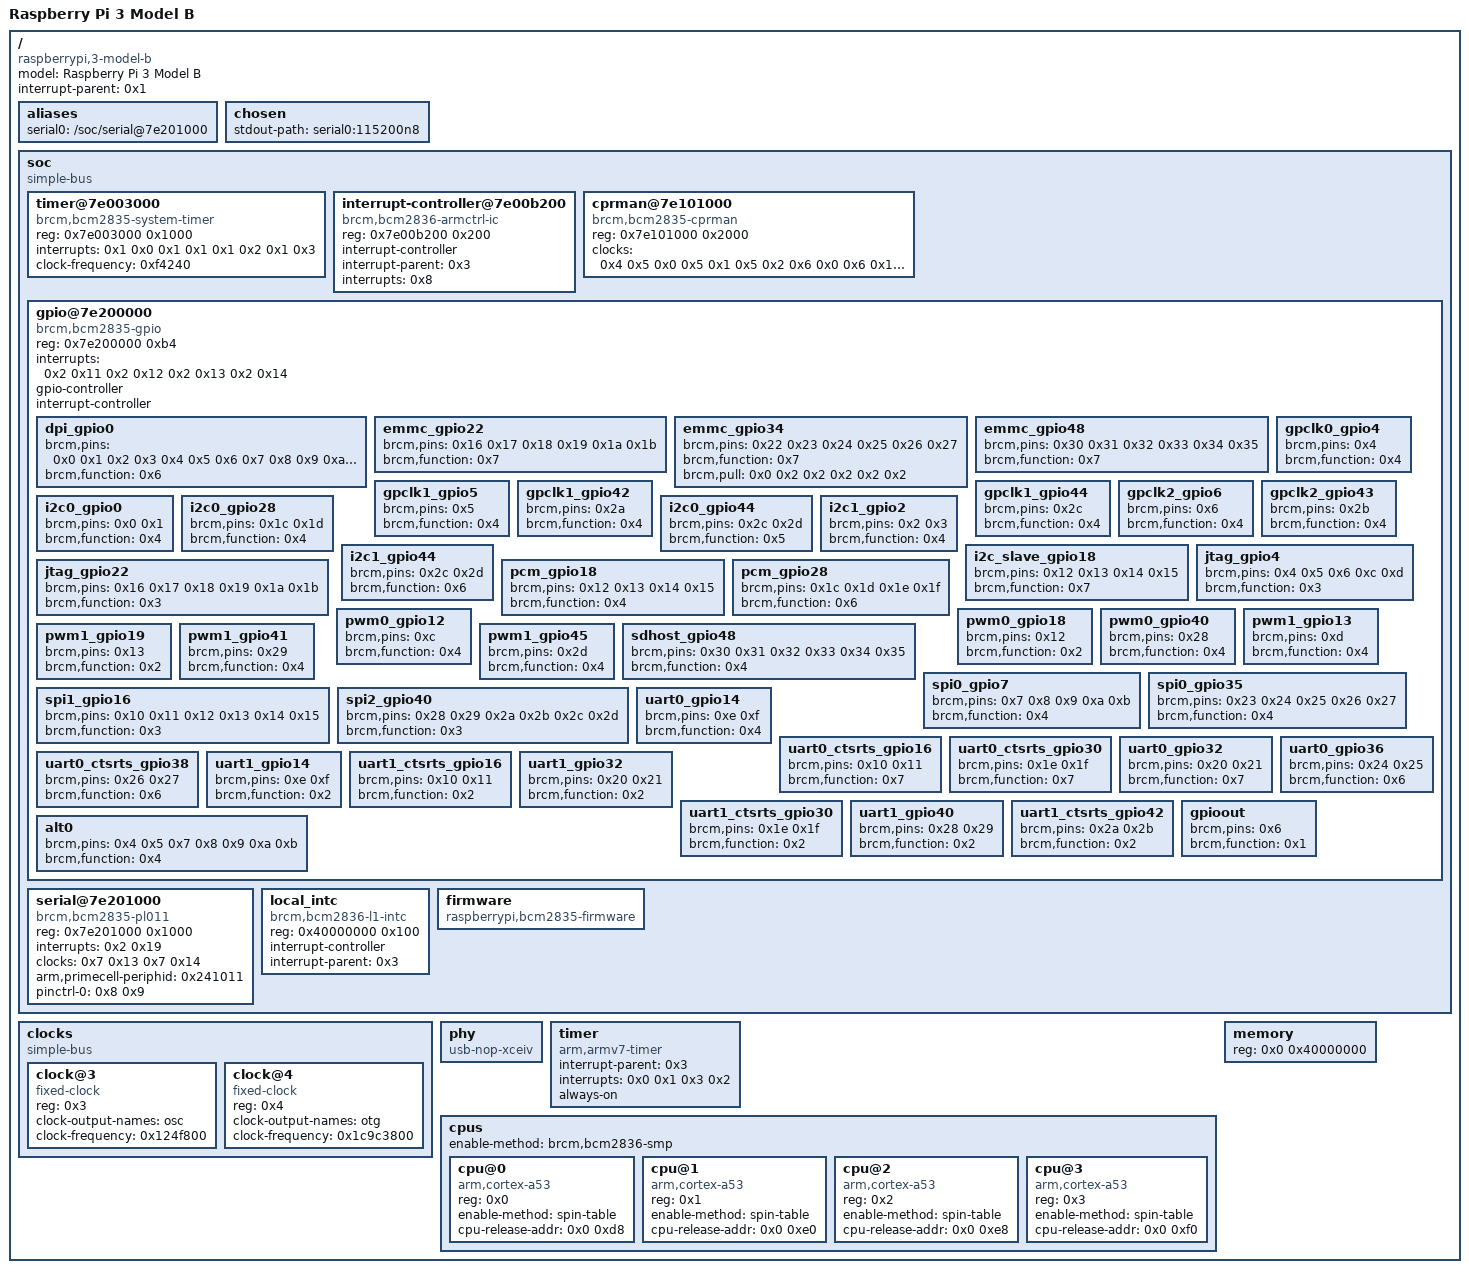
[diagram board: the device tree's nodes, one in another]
/dts-v1/;

/memreserve/	0x0000000000000000 0x0000000000001000;
/ {
	compatible = "raspberrypi,3-model-b", "brcm,bcm2837";
	model = "Raspberry Pi 3 Model B";
	interrupt-parent = <0x1>;
	#address-cells = <0x1>;
	#size-cells = <0x1>;

	aliases {
		serial0 = "/soc/serial@7e201000";
	};

	chosen {
		stdout-path = "serial0:115200n8";
	};

	soc {
		compatible = "simple-bus";
		#address-cells = <0x1>;
		#size-cells = <0x1>;
		ranges = <0x7e000000 0x3f000000 0x1000000 0x40000000 0x40000000 0x1000>;

		timer@7e003000 {
			compatible = "brcm,bcm2835-system-timer";
			reg = <0x7e003000 0x1000>;
			interrupts = <0x1 0x0 0x1 0x1 0x1 0x2 0x1 0x3>;
			clock-frequency = <0xf4240>;
		};

		interrupt-controller@7e00b200 {
			compatible = "brcm,bcm2836-armctrl-ic";
			reg = <0x7e00b200 0x200>;
			interrupt-controller;
			#interrupt-cells = <0x2>;
			interrupt-parent = <0x3>;
			interrupts = <0x8>;
			linux,phandle = <0x1>;
			phandle = <0x1>;
		};

		cprman@7e101000 {
			compatible = "brcm,bcm2835-cprman";
			#clock-cells = <0x1>;
			reg = <0x7e101000 0x2000>;
			clocks = <0x4 0x5 0x0 0x5 0x1 0x5 0x2 0x6 0x0 0x6 0x1 0x6 0x2>;
			linux,phandle = <0x7>;
			phandle = <0x7>;
		};

		gpio@7e200000 {
			compatible = "brcm,bcm2835-gpio";
			reg = <0x7e200000 0xb4>;
			interrupts = <0x2 0x11 0x2 0x12 0x2 0x13 0x2 0x14>;
			gpio-controller;
			#gpio-cells = <0x2>;
			interrupt-controller;
			#interrupt-cells = <0x2>;
			pinctrl-names = "default";
			linux,phandle = <0x19>;
			phandle = <0x19>;

			dpi_gpio0 {
				brcm,pins = <0x0 0x1 0x2 0x3 0x4 0x5 0x6 0x7 0x8 0x9 0xa 0xb 0xc 0xd 0xe 0xf 0x10 0x11 0x12 0x13 0x14 0x15 0x16 0x17 0x18 0x19 0x1a 0x1b>;
				brcm,function = <0x6>;
			};

			emmc_gpio22 {
				brcm,pins = <0x16 0x17 0x18 0x19 0x1a 0x1b>;
				brcm,function = <0x7>;
			};

			emmc_gpio34 {
				brcm,pins = <0x22 0x23 0x24 0x25 0x26 0x27>;
				brcm,function = <0x7>;
				brcm,pull = <0x0 0x2 0x2 0x2 0x2 0x2>;
				linux,phandle = <0x12>;
				phandle = <0x12>;
			};

			emmc_gpio48 {
				brcm,pins = <0x30 0x31 0x32 0x33 0x34 0x35>;
				brcm,function = <0x7>;
			};

			gpclk0_gpio4 {
				brcm,pins = <0x4>;
				brcm,function = <0x4>;
			};

			gpclk1_gpio5 {
				brcm,pins = <0x5>;
				brcm,function = <0x4>;
			};

			gpclk1_gpio42 {
				brcm,pins = <0x2a>;
				brcm,function = <0x4>;
			};

			gpclk1_gpio44 {
				brcm,pins = <0x2c>;
				brcm,function = <0x4>;
			};

			gpclk2_gpio6 {
				brcm,pins = <0x6>;
				brcm,function = <0x4>;
			};

			gpclk2_gpio43 {
				brcm,pins = <0x2b>;
				brcm,function = <0x4>;
				linux,phandle = <0x9>;
				phandle = <0x9>;
			};

			i2c0_gpio0 {
				brcm,pins = <0x0 0x1>;
				brcm,function = <0x4>;
				linux,phandle = <0xc>;
				phandle = <0xc>;
			};

			i2c0_gpio28 {
				brcm,pins = <0x1c 0x1d>;
				brcm,function = <0x4>;
			};

			i2c0_gpio44 {
				brcm,pins = <0x2c 0x2d>;
				brcm,function = <0x5>;
			};

			i2c1_gpio2 {
				brcm,pins = <0x2 0x3>;
				brcm,function = <0x4>;
				linux,phandle = <0x13>;
				phandle = <0x13>;
			};

			i2c1_gpio44 {
				brcm,pins = <0x2c 0x2d>;
				brcm,function = <0x6>;
			};

			i2c_slave_gpio18 {
				brcm,pins = <0x12 0x13 0x14 0x15>;
				brcm,function = <0x7>;
			};

			jtag_gpio4 {
				brcm,pins = <0x4 0x5 0x6 0xc 0xd>;
				brcm,function = <0x3>;
			};

			jtag_gpio22 {
				brcm,pins = <0x16 0x17 0x18 0x19 0x1a 0x1b>;
				brcm,function = <0x3>;
			};

			pcm_gpio18 {
				brcm,pins = <0x12 0x13 0x14 0x15>;
				brcm,function = <0x4>;
			};

			pcm_gpio28 {
				brcm,pins = <0x1c 0x1d 0x1e 0x1f>;
				brcm,function = <0x6>;
			};

			pwm0_gpio12 {
				brcm,pins = <0xc>;
				brcm,function = <0x4>;
			};

			pwm0_gpio18 {
				brcm,pins = <0x12>;
				brcm,function = <0x2>;
			};

			pwm0_gpio40 {
				brcm,pins = <0x28>;
				brcm,function = <0x4>;
				linux,phandle = <0x10>;
				phandle = <0x10>;
			};

			pwm1_gpio13 {
				brcm,pins = <0xd>;
				brcm,function = <0x4>;
			};

			pwm1_gpio19 {
				brcm,pins = <0x13>;
				brcm,function = <0x2>;
			};

			pwm1_gpio41 {
				brcm,pins = <0x29>;
				brcm,function = <0x4>;
			};

			pwm1_gpio45 {
				brcm,pins = <0x2d>;
				brcm,function = <0x4>;
				linux,phandle = <0x11>;
				phandle = <0x11>;
			};

			sdhost_gpio48 {
				brcm,pins = <0x30 0x31 0x32 0x33 0x34 0x35>;
				brcm,function = <0x4>;
				linux,phandle = <0xb>;
				phandle = <0xb>;
			};

			spi0_gpio7 {
				brcm,pins = <0x7 0x8 0x9 0xa 0xb>;
				brcm,function = <0x4>;
			};

			spi0_gpio35 {
				brcm,pins = <0x23 0x24 0x25 0x26 0x27>;
				brcm,function = <0x4>;
			};

			spi1_gpio16 {
				brcm,pins = <0x10 0x11 0x12 0x13 0x14 0x15>;
				brcm,function = <0x3>;
			};

			spi2_gpio40 {
				brcm,pins = <0x28 0x29 0x2a 0x2b 0x2c 0x2d>;
				brcm,function = <0x3>;
			};

			uart0_gpio14 {
				brcm,pins = <0xe 0xf>;
				brcm,function = <0x4>;
			};

			uart0_ctsrts_gpio16 {
				brcm,pins = <0x10 0x11>;
				brcm,function = <0x7>;
			};

			uart0_ctsrts_gpio30 {
				brcm,pins = <0x1e 0x1f>;
				brcm,function = <0x7>;
			};

			uart0_gpio32 {
				brcm,pins = <0x20 0x21>;
				brcm,function = <0x7>;
				linux,phandle = <0x8>;
				phandle = <0x8>;
			};

			uart0_gpio36 {
				brcm,pins = <0x24 0x25>;
				brcm,function = <0x6>;
			};

			uart0_ctsrts_gpio38 {
				brcm,pins = <0x26 0x27>;
				brcm,function = <0x6>;
			};

			uart1_gpio14 {
				brcm,pins = <0xe 0xf>;
				brcm,function = <0x2>;
				linux,phandle = <0xf>;
				phandle = <0xf>;
			};

			uart1_ctsrts_gpio16 {
				brcm,pins = <0x10 0x11>;
				brcm,function = <0x2>;
			};

			uart1_gpio32 {
				brcm,pins = <0x20 0x21>;
				brcm,function = <0x2>;
			};

			uart1_ctsrts_gpio30 {
				brcm,pins = <0x1e 0x1f>;
				brcm,function = <0x2>;
			};

			uart1_gpio40 {
				brcm,pins = <0x28 0x29>;
				brcm,function = <0x2>;
			};

			uart1_ctsrts_gpio42 {
				brcm,pins = <0x2a 0x2b>;
				brcm,function = <0x2>;
			};

			gpioout {
				brcm,pins = <0x6>;
				brcm,function = <0x1>;
			};

			alt0 {
				brcm,pins = <0x4 0x5 0x7 0x8 0x9 0xa 0xb>;
				brcm,function = <0x4>;
			};
		};

		serial@7e201000 {
			compatible = "brcm,bcm2835-pl011", "arm,pl011", "arm,primecell";
			reg = <0x7e201000 0x1000>;
			interrupts = <0x2 0x19>;
			clocks = <0x7 0x13 0x7 0x14>;
			clock-names = "uartclk", "apb_pclk";
			arm,primecell-periphid = <0x241011>;
			pinctrl-names = "default";
			pinctrl-0 = <0x8 0x9>;
			status = "okay";
		};

		local_intc {
			compatible = "brcm,bcm2836-l1-intc";
			reg = <0x40000000 0x100>;
			interrupt-controller;
			#interrupt-cells = <0x1>;
			interrupt-parent = <0x3>;
			linux,phandle = <0x3>;
			phandle = <0x3>;
		};

		firmware {
			compatible = "raspberrypi,bcm2835-firmware";
			linux,phandle = <0x18>;
			phandle = <0x18>;
		};
	};

	clocks {
		compatible = "simple-bus";
		#address-cells = <0x1>;
		#size-cells = <0x0>;

		clock@3 {
			compatible = "fixed-clock";
			reg = <0x3>;
			#clock-cells = <0x0>;
			clock-output-names = "osc";
			clock-frequency = <0x124f800>;
			linux,phandle = <0x4>;
			phandle = <0x4>;
		};

		clock@4 {
			compatible = "fixed-clock";
			reg = <0x4>;
			#clock-cells = <0x0>;
			clock-output-names = "otg";
			clock-frequency = <0x1c9c3800>;
			linux,phandle = <0x15>;
			phandle = <0x15>;
		};
	};

	phy {
		compatible = "usb-nop-xceiv";
		#phy-cells = <0x0>;
		linux,phandle = <0x16>;
		phandle = <0x16>;
	};

	timer {
		compatible = "arm,armv7-timer";
		interrupt-parent = <0x3>;
		interrupts = <0x0 0x1 0x3 0x2>;
		always-on;
	};

	cpus {
		#address-cells = <0x1>;
		#size-cells = <0x0>;
		enable-method = "brcm,bcm2836-smp";

		cpu@0 {
			device_type = "cpu";
			compatible = "arm,cortex-a53";
			reg = <0x0>;
			enable-method = "spin-table";
			cpu-release-addr = <0x0 0xd8>;
		};

		cpu@1 {
			device_type = "cpu";
			compatible = "arm,cortex-a53";
			reg = <0x1>;
			enable-method = "spin-table";
			cpu-release-addr = <0x0 0xe0>;
		};

		cpu@2 {
			device_type = "cpu";
			compatible = "arm,cortex-a53";
			reg = <0x2>;
			enable-method = "spin-table";
			cpu-release-addr = <0x0 0xe8>;
		};

		cpu@3 {
			device_type = "cpu";
			compatible = "arm,cortex-a53";
			reg = <0x3>;
			enable-method = "spin-table";
			cpu-release-addr = <0x0 0xf0>;
		};
	};

	memory {
		device_type = "memory";
		reg = <0x0 0x40000000>;
	};
};
